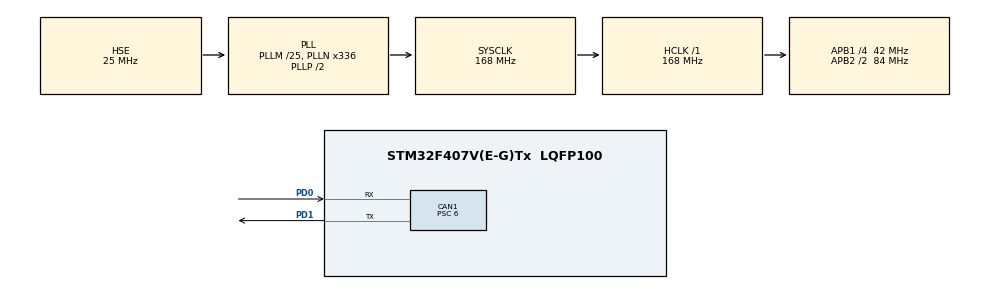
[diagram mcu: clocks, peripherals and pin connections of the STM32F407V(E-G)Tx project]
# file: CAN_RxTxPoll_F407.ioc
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CAN1.ABOM=ENABLE
CAN1.BS1=CAN_BS1_10TQ
CAN1.BS2=CAN_BS2_3TQ
CAN1.CalculateBaudRate=500000
CAN1.CalculateTimeBit=2000
CAN1.CalculateTimeQuantum=142.85714285714286
CAN1.NART=ENABLE
CAN1.Prescaler=6
Mcu.Family=STM32F4
Mcu.Name=STM32F407V(E-G)Tx
Mcu.Package=LQFP100
NVIC.PriorityGroup=NVIC_PRIORITYGROUP_4
PA13.Mode=Serial_Wire
PA13.Signal=SYS_JTMS-SWDIO
PA14.Mode=Serial_Wire
PA14.Signal=SYS_JTCK-SWCLK
PD0.Mode=CAN_Activate
PD0.Signal=CAN1_RX
PD1.Mode=CAN_Activate
PD1.Signal=CAN1_TX
PH0-OSC_IN.Mode=HSE-External-Oscillator
PH0-OSC_IN.Signal=RCC_OSC_IN
PH1-OSC_OUT.Mode=HSE-External-Oscillator
PH1-OSC_OUT.Signal=RCC_OSC_OUT
ProjectManager.HeapSize=0x200
ProjectManager.StackSize=0x400
ProjectManager.TargetToolchain=STM32CubeIDE
RCC.48MHZClocksFreq_Value=84000000
RCC.AHBFreq_Value=168000000
RCC.APB1CLKDivider=RCC_HCLK_DIV4
RCC.APB1Freq_Value=42000000
RCC.APB1TimFreq_Value=84000000
RCC.APB2CLKDivider=RCC_HCLK_DIV2
RCC.APB2Freq_Value=84000000
RCC.APB2TimFreq_Value=168000000
RCC.CortexFreq_Value=168000000
RCC.HCLKFreq_Value=168000000
RCC.HSE_VALUE=25000000
RCC.HSI_VALUE=16000000
RCC.LSE_VALUE=32768
RCC.PLLM=25
RCC.PLLN=336
RCC.PLLSourceVirtual=RCC_PLLSOURCE_HSE
RCC.SYSCLKFreq_VALUE=168000000
RCC.SYSCLKSource=RCC_SYSCLKSOURCE_PLLCLK
RCC.VCOOutputFreq_Value=336000000
board=custom

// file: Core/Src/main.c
/* USER CODE BEGIN Header */
/**
  ******************************************************************************
  * @file           : main.c
  * @brief          : Main program body
  ******************************************************************************
  * @attention
  *
  * Copyright (c) 2023 STMicroelectronics.
  * All rights reserved.
  *
  * This software is licensed under terms that can be found in the LICENSE file
  * in the root directory of this software component.
  * If no LICENSE file comes with this software, it is provided AS-IS.
  *
  ******************************************************************************
  */
/* USER CODE END Header */
#include "main.h"

CAN_HandleTypeDef hcan1;

void SystemClock_Config(void);
static void MX_GPIO_Init(void);
static void MX_CAN1_Init(void);

int main(void)
{

  /* MCU Configuration--------------------------------------------------------*/

  /* Reset of all peripherals, Initializes the Flash interface and the Systick. */
  HAL_Init();

  /* Configure the system clock */
  SystemClock_Config();

  /* Initialize all configured peripherals */
  MX_GPIO_Init();
  MX_CAN1_Init();

  /* Infinite loop */
  /* USER CODE BEGIN WHILE */

  /**************** 以下为过滤器设置 ****************/
  CAN_FilterTypeDef  sFilterConfig;

  sFilterConfig.FilterMode = CAN_FILTERMODE_IDMASK; // 使用MASK模式
  sFilterConfig.FilterScale = CAN_FILTERSCALE_32BIT; // 过滤器使用32bit模式
  sFilterConfig.FilterIdHigh = 0x0000;
  sFilterConfig.FilterIdLow = 0x0000;
  sFilterConfig.FilterMaskIdHigh = 0x0000;
  sFilterConfig.FilterMaskIdLow = 0x0000;
  sFilterConfig.FilterFIFOAssignment = CAN_RX_FIFO0; // 经过过滤的数据放到FIFO0
  sFilterConfig.FilterBank = 0; // 使用第0组过滤器
  sFilterConfig.SlaveStartFilterBank = 14; // 从CAN过滤器其实地址
  sFilterConfig.FilterActivation = ENABLE; // 使能过滤器

  if(HAL_CAN_ConfigFilter(&hcan1, &sFilterConfig) != HAL_OK)
  {
    // 过滤器设置失败
  }

  /**************** 以下为启动CAN外设 ****************/
  HAL_CAN_Start(&hcan1); // 启动CAN

  while (1)
  {

	/**************** 以下为接收消息并回发处理 ****************/
	if(HAL_CAN_GetRxFifoFillLevel(&hcan1, CAN_RX_FIFO0) != 0) // 接收队列不为0，有数据可读
	{
		CAN_RxHeaderTypeDef   RxHeader; // 用来保存接收到的数据帧头部信息
		uint8_t               RxData[8]; // 用来保存接收数据端数据

		if(HAL_CAN_GetRxMessage(&hcan1, CAN_RX_FIFO0, &RxHeader, RxData) == HAL_OK) // 从接收队列中读取数据帧
		{
			CAN_TxHeaderTypeDef   TxHeader; // 用来保存发送数据帧头部信息
			uint8_t               TxData[8]; // 用来保存发送数据帧数据
			uint32_t              TxMailbox; // 用来保存发送数据帧所使用的邮箱号

			if(RxHeader.IDE == CAN_ID_STD) // 标准数据帧
			{
				TxHeader.StdId = RxHeader.StdId; // 标准帧ID
			}
			if(RxHeader.IDE == CAN_ID_EXT) // 扩展数据帧
			{
				TxHeader.ExtId = RxHeader.ExtId; // 扩展帧ID
			}
			TxHeader.IDE = RxHeader.IDE; // ID类型

			TxHeader.RTR = RxHeader.RTR; // CAN_RTR_DATA 数据帧；CAN_RTR_REMOTE 远程帧

			TxHeader.DLC = RxHeader.DLC; // 数据段字节数

			for(int i=0; i<TxHeader.DLC; i++)
			{
				TxData[i] = RxData[i];
			}

			while(HAL_CAN_GetTxMailboxesFreeLevel(&hcan1) == 0); // 等待有发送邮箱可用

			HAL_CAN_AddTxMessage(&hcan1, &TxHeader, TxData, &TxMailbox); // 发送数据帧
		}
	}

    /* USER CODE END WHILE */

  }
}

void SystemClock_Config(void)
{
  RCC_OscInitTypeDef RCC_OscInitStruct = {0};
  RCC_ClkInitTypeDef RCC_ClkInitStruct = {0};

  /** Configure the main internal regulator output voltage
  */
  __HAL_RCC_PWR_CLK_ENABLE();
  __HAL_PWR_VOLTAGESCALING_CONFIG(PWR_REGULATOR_VOLTAGE_SCALE1);

  /** Initializes the RCC Oscillators according to the specified parameters
  * in the RCC_OscInitTypeDef structure.
  */
  RCC_OscInitStruct.OscillatorType = RCC_OSCILLATORTYPE_HSE;
  RCC_OscInitStruct.HSEState = RCC_HSE_ON;
  RCC_OscInitStruct.PLL.PLLState = RCC_PLL_ON;
  RCC_OscInitStruct.PLL.PLLSource = RCC_PLLSOURCE_HSE;
  RCC_OscInitStruct.PLL.PLLM = 25;
  RCC_OscInitStruct.PLL.PLLN = 336;
  RCC_OscInitStruct.PLL.PLLP = RCC_PLLP_DIV2;
  RCC_OscInitStruct.PLL.PLLQ = 4;
  if (HAL_RCC_OscConfig(&RCC_OscInitStruct) != HAL_OK)
  {
    Error_Handler();
  }

  /** Initializes the CPU, AHB and APB buses clocks
  */
  RCC_ClkInitStruct.ClockType = RCC_CLOCKTYPE_HCLK|RCC_CLOCKTYPE_SYSCLK
                              |RCC_CLOCKTYPE_PCLK1|RCC_CLOCKTYPE_PCLK2;
  RCC_ClkInitStruct.SYSCLKSource = RCC_SYSCLKSOURCE_PLLCLK;
  RCC_ClkInitStruct.AHBCLKDivider = RCC_SYSCLK_DIV1;
  RCC_ClkInitStruct.APB1CLKDivider = RCC_HCLK_DIV4;
  RCC_ClkInitStruct.APB2CLKDivider = RCC_HCLK_DIV2;

  if (HAL_RCC_ClockConfig(&RCC_ClkInitStruct, FLASH_LATENCY_5) != HAL_OK)
  {
    Error_Handler();
  }
}

static void MX_CAN1_Init(void)
{

  hcan1.Instance = CAN1;
  hcan1.Init.Prescaler = 6;
  hcan1.Init.Mode = CAN_MODE_NORMAL;
  hcan1.Init.SyncJumpWidth = CAN_SJW_1TQ;
  hcan1.Init.TimeSeg1 = CAN_BS1_10TQ;
  hcan1.Init.TimeSeg2 = CAN_BS2_3TQ;
  hcan1.Init.TimeTriggeredMode = DISABLE;
  hcan1.Init.AutoBusOff = ENABLE;
  hcan1.Init.AutoWakeUp = DISABLE;
  hcan1.Init.AutoRetransmission = ENABLE;
  hcan1.Init.ReceiveFifoLocked = DISABLE;
  hcan1.Init.TransmitFifoPriority = DISABLE;
  if (HAL_CAN_Init(&hcan1) != HAL_OK)
  {
    Error_Handler();
  }

}

static void MX_GPIO_Init(void)
{

  /* GPIO Ports Clock Enable */
  __HAL_RCC_GPIOH_CLK_ENABLE();
  __HAL_RCC_GPIOA_CLK_ENABLE();
  __HAL_RCC_GPIOD_CLK_ENABLE();

}

void Error_Handler(void)
{
  __disable_irq();
  while (1)
  {
  }
}
